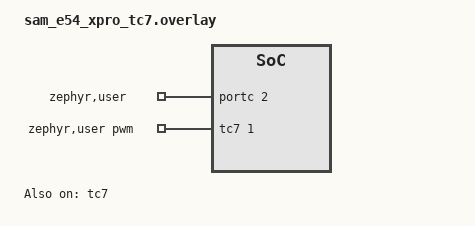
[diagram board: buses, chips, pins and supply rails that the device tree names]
/*
 * Copyright (c) 2025 Microchip Technology Inc.
 *
 * SPDX-License-Identifier: Apache-2.0
 */

/* connect the PB01 to PC02 */

#include <zephyr/dt-bindings/gpio/gpio.h>

/ {
	zephyr,user {
		pwms = <&tc7 1 PWM_MSEC(1) 1>;
		gpios = <&portc 2 GPIO_ACTIVE_HIGH>;
	};
};

&tc7 {
	status = "okay";
	compatible = "microchip,tc-g1-pwm";
	#pwm-cells = <3>;
	pinctrl-0 = <&tc7_pwm_default>;
	pinctrl-names = "default";
	prescaler = <4>;
};

&pinctrl {
	tc7_pwm_default: tc7_pwm_default {
		group1 {
			pinmux = <PB1E_TC7_WO1>;
		};
	};
};
